AUTOSAR XML (schema 4-0-3)
package /EcuM/ServiceSwComponentTypes
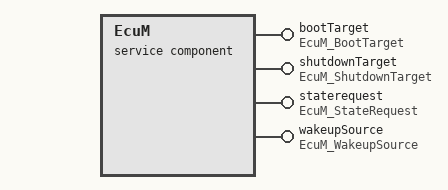
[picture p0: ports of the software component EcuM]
  service sw component type EcuM
    4 x provide port:
      bootTarget: provided-com-specs=[{operation=GetBootTarget, queue-length=1}, {operation=SelectBootTarget, queue-length=1}], provided-interface=EcuM_BootTarget
      shutdownTarget: provided-interface=EcuM_ShutdownTarget
        provided-com-specs:
          operation=GetLastShutdownTarget, queue-length=1
          operation=GetMostRecentShutdown, queue-length=1
          operation=GetNextRecentShutdown, queue-length=1
          operation=GetShutdownCause, queue-length=1
          operation=GetShutdownTarget, queue-length=1
          operation=GoDown, queue-length=1
          operation=GoHalt, queue-length=1
          operation=GoPoll, queue-length=1
          operation=SelectShutdownCause, queue-length=1
          operation=SelectShutdownTarget, queue-length=1
      staterequest: provided-interface=EcuM_StateRequest
        provided-com-specs:
          operation=ReleaseRUN, queue-length=1
          operation=RequestOff, queue-length=1
          operation=RequestRUN, queue-length=1
          operation=RequestReset, queue-length=1
          operation=RequestSleep, queue-length=1
          operation=SetRunState, queue-length=1
      wakeupSource: provided-interface=EcuM_WakeupSource
        provided-com-specs:
          operation=ClearWakeupEvent, queue-length=1
          operation=DisableWakeupSources, queue-length=1
          operation=EnableWakeupSources, queue-length=1
    behavior SwcIB_EcuM: handle-termination-and-restart=NO-SUPPORT, included-data-type-set=data-type=EcuM_RequestType
      21 x operation invoked event:
        OIE_GetBootTarget: start-on-event=GetBootTarget, operation=bootTarget.GetBootTarget
        OIE_SelectBootTarget: start-on-event=SelectBootTarget, operation=bootTarget.SelectBootTarget
        OIE_GetLastShutdownTarget: start-on-event=GetLastShutdownTarget, operation=shutdownTarget.GetLastShutdownTarget
        OIE_GetMostRecentShutdown: start-on-event=GetMostRecentShutdown, operation=shutdownTarget.GetMostRecentShutdown
        OIE_GetNextRecentShutdown: start-on-event=GetNextRecentShutdown, operation=shutdownTarget.GetNextRecentShutdown
        OIE_GetShutdownCause: start-on-event=GetShutdownCause, operation=shutdownTarget.GetShutdownCause
        OIE_GetShutdownTarget: start-on-event=GetShutdownTarget, operation=shutdownTarget.GetShutdownTarget
        OIE_GoDown: start-on-event=GoDown, operation=shutdownTarget.GoDown
        OIE_GoHalt: start-on-event=GoHalt, operation=shutdownTarget.GoHalt
        OIE_GoPoll: start-on-event=GoPoll, operation=shutdownTarget.GoPoll
        OIE_SelectShutdownCause: start-on-event=SelectShutdownCause, operation=shutdownTarget.SelectShutdownCause
        OIE_SelectShutdownTarget: start-on-event=SelectShutdownTarget, operation=shutdownTarget.SelectShutdownTarget
        OIE_ReleaseRUN: start-on-event=ReleaseRUN, operation=staterequest.ReleaseRUN
        OIE_RequestOff: start-on-event=RequestOff, operation=staterequest.RequestOff
        OIE_RequestRUN: start-on-event=RequestRUN, operation=staterequest.RequestRUN
        OIE_RequestReset: start-on-event=RequestReset, operation=staterequest.RequestReset
        OIE_RequestSleep: start-on-event=RequestSleep, operation=staterequest.RequestSleep
        OIE_SetRunState: start-on-event=SetRunState, operation=staterequest.SetRunState
        OIE_ClearWakeupEvent: start-on-event=ClearWakeupEvent, operation=wakeupSource.ClearWakeupEvent
        OIE_DisableWakeupSources: start-on-event=DisableWakeupSources, operation=wakeupSource.DisableWakeupSources
        OIE_EnableWakeupSources: start-on-event=EnableWakeupSources, operation=wakeupSource.EnableWakeupSources
      21 x runnable, all with can-be-invoked-concurrently=true:
        GetBootTarget: symbol=EcuM_GetBootTarget
        SelectBootTarget: symbol=EcuM_SelectBootTarget
        GetLastShutdownTarget: symbol=EcuM_GetLastShutdownTarget
        GetMostRecentShutdown: symbol=EcuM_GetMostRecentShutdown
        GetNextRecentShutdown: symbol=EcuM_GetNextRecentShutdown
        GetShutdownCause: symbol=EcuM_GetShutdownCause
        GetShutdownTarget: symbol=EcuM_GetShutdownTarget
        GoDown: symbol=EcuM_GoDown
        GoHalt: symbol=EcuM_GoHalt
        GoPoll: symbol=EcuM_GoPoll
        SelectShutdownCause: symbol=EcuM_SelectShutdownCause
        SelectShutdownTarget: symbol=EcuM_SelectShutdownTarget
        ReleaseRUN: symbol=EcuM_ReleaseRUN
        RequestOff: symbol=EcuM_RequestOff
        RequestRUN: symbol=EcuM_RequestRUN
        RequestReset: symbol=EcuM_RequestReset
        RequestSleep: symbol=EcuM_RequestSleep
        SetRunState: symbol=EcuM_SetRunState
        ClearWakeupEvent: symbol=EcuM_ClearWakeupEvent
        DisableWakeupSources: symbol=EcuM_DisableWakeupSources
        EnableWakeupSources: symbol=EcuM_EnableWakeupSources
  swc implementation SwcImplementation_EcuM: programming-language=C, swc-bsw-mapping=SwcBswMapping_EcuM, behavior=SwcIB_EcuM
  swc bsw mapping SwcBswMapping_EcuM: bsw-behavior=BswIB_EcuM, swc-behavior=SwcIB_EcuM
